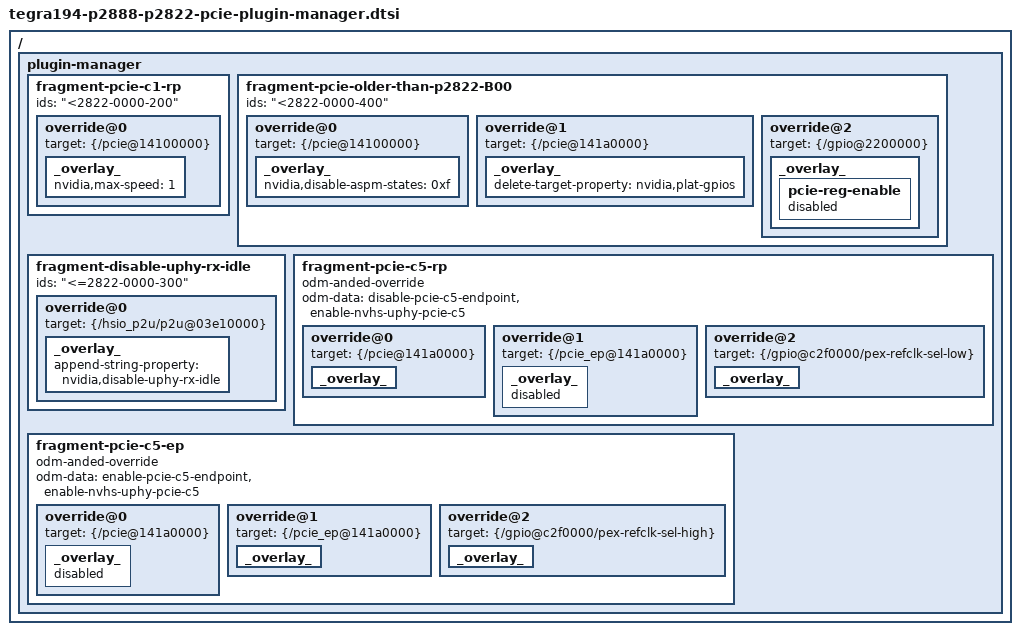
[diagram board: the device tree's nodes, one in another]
/*
 * Copyright (c) 2018, NVIDIA CORPORATION.  All rights reserved.
 *
 * This program is free software; you can redistribute it and/or modify
 * it under the terms of the GNU General Public License as published by
 * the Free Software Foundation; either version 2 of the License, or
 * (at your option) any later version.
 *
 * This program is distributed in the hope that it will be useful, but WITHOUT
 * ANY WARRANTY; without even the implied warranty of MERCHANTABILITY or
 * FITNESS FOR A PARTICULAR PURPOSE.  See the GNU General Public License for
 * more details.
 */

/ {
	plugin-manager {
		fragment-pcie-c1-rp {
			ids = "<2822-0000-200";
			override@0 {
				target = <&{/pcie@14100000}>;
				_overlay_ {
					nvidia,max-speed = <1>;
				};
			};
		};

		fragment-pcie-older-than-p2822-B00 {
			ids = "<2822-0000-400";
			override@0 {
				target = <&{/pcie@14100000}>;
				_overlay_ {
					nvidia,disable-aspm-states = <0xf>;
				};
			};
			override@1 {
				target = <&{/pcie@141a0000}>;
				_overlay_ {
					delete-target-property = "nvidia,plat-gpios";
				};
			};
			override@2 {
				target = <&{/gpio@2200000}>;
				_overlay_ {
					pcie-reg-enable {
						status = "disabled";
					};
				};
			};
		};

		fragment-disable-uphy-rx-idle {
			ids = "<=2822-0000-300";
			override@0 {
				target = <&{/hsio_p2u/p2u@03e10000}>;
				_overlay_ {
					append-string-property = "nvidia,disable-uphy-rx-idle";
				};
			};
		};

		fragment-pcie-c5-rp {
			odm-anded-override;
			odm-data = "disable-pcie-c5-endpoint", "enable-nvhs-uphy-pcie-c5";
			override@0 {
				target = <&{/pcie@141a0000}>;
				_overlay_ {
					status = "okay";
				};
			};
			override@1 {
				target = <&{/pcie_ep@141a0000}>;
				_overlay_ {
					status = "disabled";
				};
			};
			override@2 {
				target = <&{/gpio@c2f0000/pex-refclk-sel-low}>;
				_overlay_ {
					status = "okay";
				};
			};
		};

		fragment-pcie-c5-ep {
			odm-anded-override;
			odm-data = "enable-pcie-c5-endpoint", "enable-nvhs-uphy-pcie-c5";
			override@0 {
				target = <&{/pcie@141a0000}>;
				_overlay_ {
					status = "disabled";
				};
			};
			override@1 {
				target = <&{/pcie_ep@141a0000}>;
				_overlay_ {
					status = "okay";
				};
			};
			override@2 {
				target = <&{/gpio@c2f0000/pex-refclk-sel-high}>;
				_overlay_ {
					status = "okay";
				};
			};
		};
	};
};
